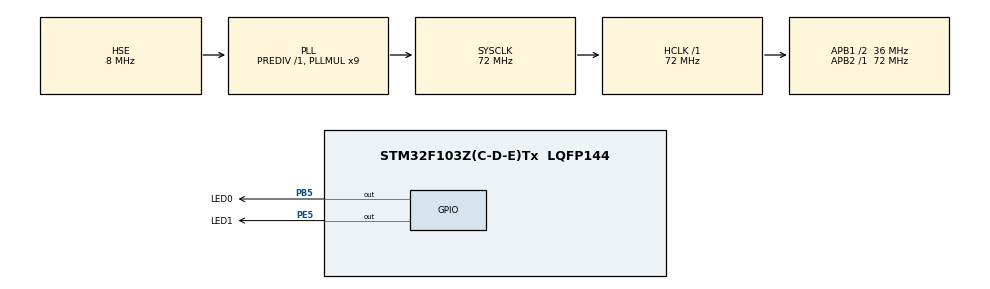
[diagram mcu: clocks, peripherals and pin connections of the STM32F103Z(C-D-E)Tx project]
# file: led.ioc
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Mcu.Family=STM32F1
RCC.PLLSourceVirtual=RCC_PLLSOURCE_HSE
PC15-OSC32_OUT.Mode=LSE-External-Oscillator
RCC.APB1CLKDivider=RCC_HCLK_DIV2
PC14-OSC32_IN.Signal=RCC_OSC32_IN
VP_SYS_VS_ND.Mode=No_Debug
RCC.SYSCLKSource=RCC_SYSCLKSOURCE_PLLCLK
ProjectManager.StackSize=0x400
ProjectManager.TargetToolchain=STM32CubeIDE
RCC.HCLKFreq_Value=72000000
RCC.APB2TimFreq_Value=72000000
PB5.PinState=GPIO_PIN_SET
PE5.Signal=GPIO_Output
OSC_IN.Signal=RCC_OSC_IN
RCC.USBFreq_Value=72000000
OSC_OUT.Mode=HSE-External-Oscillator
PC15-OSC32_OUT.Signal=RCC_OSC32_OUT
OSC_OUT.Signal=RCC_OSC_OUT
RCC.AHBFreq_Value=72000000
board=custom
RCC.PLLMUL=RCC_PLL_MUL9
RCC.APB2Freq_Value=72000000
PC14-OSC32_IN.Mode=LSE-External-Oscillator
PE5.PinState=GPIO_PIN_SET
Mcu.Name=STM32F103Z(C-D-E)Tx
RCC.SYSCLKFreq_VALUE=72000000
Mcu.Package=LQFP144
PB5.Signal=GPIO_Output
OSC_IN.Mode=HSE-External-Oscillator
PE5.GPIO_Label=LED1
ProjectManager.HeapSize=0x200
PB5.GPIO_Speed=GPIO_SPEED_FREQ_HIGH
NVIC.PriorityGroup=NVIC_PRIORITYGROUP_2
PB5.GPIO_Label=LED0
PE5.GPIO_Speed=GPIO_SPEED_FREQ_HIGH
RCC.APB1TimFreq_Value=72000000
RCC.APB1Freq_Value=36000000

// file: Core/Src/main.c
/* USER CODE BEGIN Header */
/**
  ******************************************************************************
  * @file           : main.c
  * @brief          : Main program body
  ******************************************************************************
  * @attention
  *
  * <h2><center>&copy; Copyright (c) 2021 STMicroelectronics.
  * All rights reserved.</center></h2>
  *
  * This software component is licensed by ST under BSD 3-Clause license,
  * the "License"; You may not use this file except in compliance with the
  * License. You may obtain a copy of the License at:
  *                        opensource.org/licenses/BSD-3-Clause
  *
  ******************************************************************************
  */
/* USER CODE END Header */
#include "main.h"
#include "gpio.h"

void SystemClock_Config(void);

int main(void)
{
	uint32_t dwSys_time = 0;

  /* MCU Configuration--------------------------------------------------------*/

  /* Reset of all peripherals, Initializes the Flash interface and the Systick. */
  HAL_Init();

  /* Configure the system clock */
  SystemClock_Config();

  /* Initialize all configured peripherals */
  MX_GPIO_Init();

  /* Infinite loop */
  /* USER CODE BEGIN WHILE */
  while (1)
  {
		if (HAL_GetTick() - dwSys_time > 999) {
			dwSys_time = HAL_GetTick();
			HAL_GPIO_TogglePin(LED0_GPIO_Port,LED0_Pin);
			HAL_GPIO_TogglePin(LED1_GPIO_Port,LED1_Pin);
		}

    /* USER CODE END WHILE */

  }
}

void SystemClock_Config(void)
{
  RCC_OscInitTypeDef RCC_OscInitStruct = {0};
  RCC_ClkInitTypeDef RCC_ClkInitStruct = {0};

  /** Initializes the RCC Oscillators according to the specified parameters
  * in the RCC_OscInitTypeDef structure.
  */
  RCC_OscInitStruct.OscillatorType = RCC_OSCILLATORTYPE_HSE;
  RCC_OscInitStruct.HSEState = RCC_HSE_ON;
  RCC_OscInitStruct.HSEPredivValue = RCC_HSE_PREDIV_DIV1;
  RCC_OscInitStruct.HSIState = RCC_HSI_ON;
  RCC_OscInitStruct.PLL.PLLState = RCC_PLL_ON;
  RCC_OscInitStruct.PLL.PLLSource = RCC_PLLSOURCE_HSE;
  RCC_OscInitStruct.PLL.PLLMUL = RCC_PLL_MUL9;
  if (HAL_RCC_OscConfig(&RCC_OscInitStruct) != HAL_OK)
  {
    Error_Handler();
  }
  /** Initializes the CPU, AHB and APB buses clocks
  */
  RCC_ClkInitStruct.ClockType = RCC_CLOCKTYPE_HCLK|RCC_CLOCKTYPE_SYSCLK
                              |RCC_CLOCKTYPE_PCLK1|RCC_CLOCKTYPE_PCLK2;
  RCC_ClkInitStruct.SYSCLKSource = RCC_SYSCLKSOURCE_PLLCLK;
  RCC_ClkInitStruct.AHBCLKDivider = RCC_SYSCLK_DIV1;
  RCC_ClkInitStruct.APB1CLKDivider = RCC_HCLK_DIV2;
  RCC_ClkInitStruct.APB2CLKDivider = RCC_HCLK_DIV1;

  if (HAL_RCC_ClockConfig(&RCC_ClkInitStruct, FLASH_LATENCY_2) != HAL_OK)
  {
    Error_Handler();
  }
}

void Error_Handler(void)
{
  __disable_irq();
  while (1)
  {
  }
}

/************************ (C) COPYRIGHT STMicroelectronics *****END OF FILE****/
